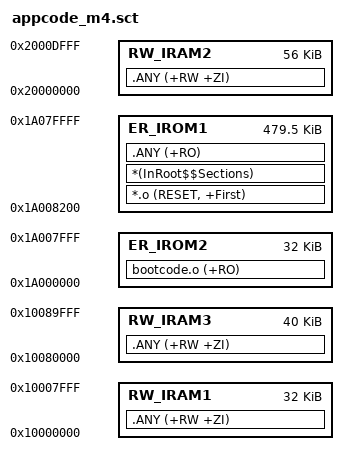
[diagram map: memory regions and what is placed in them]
; *************************************************************
; *** Scatter-Loading Description File generated by uVision ***
; *************************************************************

LR_IROM1 0x1A008200 0x00077E00  {    ; load region size_region
    ER_IROM1 0x1A008200 0x00077E00  {  ; load address = execution address
        *.o (RESET, +First)
        *(InRoot$$Sections)
        .ANY (+RO)
    }

    RW_IRAM1 0x10000000 0x00008000  {  ; RW data
        .ANY (+RW +ZI)
    }

    RW_IRAM3 0x10080000 0xA000  {
        .ANY (+RW +ZI)
    }

    RW_IRAM2 0x20000000 0x0000E000  {
        .ANY (+RW +ZI)
    }
}

; 加入bootcode.o 引入已經編譯好的Bootcode bin file
LR_IROM2 0x1A000000 0x00008000  {    ; load region size_region
  ER_IROM2 0x1A000000 0x00008000  {  ; load address = execution address
   bootcode.o (+RO)
  }
}
